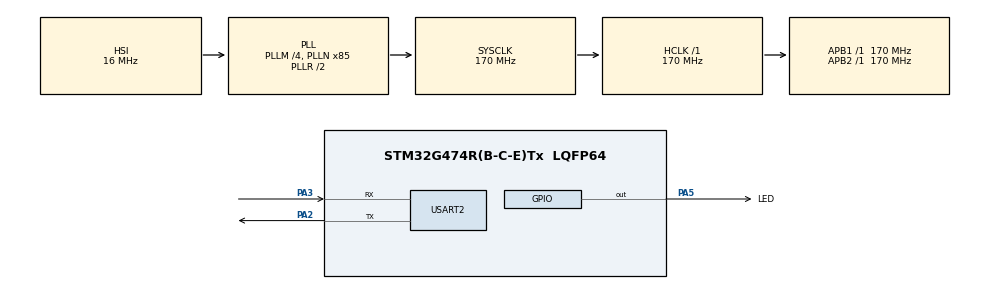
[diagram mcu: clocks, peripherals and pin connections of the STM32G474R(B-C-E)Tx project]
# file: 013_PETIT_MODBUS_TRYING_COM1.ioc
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Mcu.Family=STM32G4
Mcu.Name=STM32G474R(B-C-E)Tx
Mcu.Package=LQFP64
NVIC.PriorityGroup=NVIC_PRIORITYGROUP_4
NVIC.TIM1_UP_TIM16_IRQn=true\:0\:0\:false\:false\:true\:true\:true\:true
NVIC.USART2_IRQn=true\:0\:0\:false\:false\:true\:true\:true\:true
PA13.Mode=Serial_Wire
PA13.Signal=SYS_JTMS-SWDIO
PA14.Mode=Serial_Wire
PA14.Signal=SYS_JTCK-SWCLK
PA2.Mode=Asynchronous
PA2.Signal=USART2_TX
PA2.TagName=VCP_TX
PA3.Mode=Asynchronous
PA3.Signal=USART2_RX
PA3.TagName=VCP_RX
PA5.GPIO_Label=LED
PA5.Signal=GPIO_Output
PA5.TagName=LD2
PC13.TagName=B1
PC14-OSC32_IN.Mode=LSE-External-Oscillator
PC14-OSC32_IN.Signal=RCC_OSC32_IN
PC15-OSC32_OUT.Mode=LSE-External-Oscillator
PC15-OSC32_OUT.Signal=RCC_OSC32_OUT
PF0-OSC_IN.Mode=HSE-External-Oscillator
PF0-OSC_IN.Signal=RCC_OSC_IN
PF1-OSC_OUT.Mode=HSE-External-Oscillator
PF1-OSC_OUT.Signal=RCC_OSC_OUT
ProjectManager.HeapSize=0x200
ProjectManager.StackSize=0x400
ProjectManager.TargetToolchain=STM32CubeIDE
RCC.ADC12Freq_Value=170000000
RCC.ADC345Freq_Value=170000000
RCC.AHBFreq_Value=170000000
RCC.APB1Freq_Value=170000000
RCC.APB1TimFreq_Value=170000000
RCC.APB2Freq_Value=170000000
RCC.APB2TimFreq_Value=170000000
RCC.CortexFreq_Value=170000000
RCC.EXTERNAL_CLOCK_VALUE=12288000
RCC.HCLKFreq_Value=170000000
RCC.HSE_VALUE=24000000
RCC.HSI48_VALUE=48000000
RCC.HSI_VALUE=16000000
RCC.PLLM=RCC_PLLM_DIV4
RCC.PLLN=85
RCC.RTCClockSelection=RCC_RTCCLKSOURCE_LSE
RCC.SYSCLKFreq_VALUE=170000000
RCC.SYSCLKSource=RCC_SYSCLKSOURCE_PLLCLK
RCC.USBFreq_Value=170000000
RCC.VCOOutputFreq_Value=340000000
TIM16.PeriodNoDither=10000
TIM16.Prescaler=17000
USART2.VirtualMode-Asynchronous=VM_ASYNC
VP_SYS_VS_DBSignals.Mode=DisableDeadBatterySignals
VP_TIM16_VS_ClockSourceINT.Mode=Enable_Timer
VP_TIM1_VS_ClockSourceINT.Mode=Internal
board=NUCLEO-G474RE

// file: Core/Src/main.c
/* USER CODE BEGIN Header */
/**
  ******************************************************************************
  * @file           : main.c
  * @brief          : Main program body
  ******************************************************************************
  * @attention
  *
  * Copyright (c) 2024 STMicroelectronics.
  * All rights reserved.
  *
  * This software is licensed under terms that can be found in the LICENSE file
  * in the root directory of this software component.
  * If no LICENSE file comes with this software, it is provided AS-IS.
  *
  ******************************************************************************
  */
/* USER CODE END Header */
#include "main.h"

/* USER CODE BEGIN PD */
#define SLAVEID 1
/* USER CODE END PD */

TIM_HandleTypeDef htim1;
TIM_HandleTypeDef htim16;

UART_HandleTypeDef huart2;

void SystemClock_Config(void);
static void MX_GPIO_Init(void);
static void MX_TIM1_Init(void);
static void MX_TIM16_Init(void);
static void MX_USART2_UART_Init(void);

/* USER CODE BEGIN 0 */
int counter =0;
uint8_t rxbuffer[8];  //GELEN VERIYI TUTACAK BUFFER
uint8_t reg[10] ={0}; //10 ADET HOLDING REGISTER

void CRC16(const unsigned char Data, unsigned int* CRC)
{
    unsigned int i;

    *CRC = *CRC ^(unsigned int) Data;
    for (i = 8; i > 0; i--)
    {
        if (*CRC & 0x0001)
            *CRC = (*CRC >> 1) ^ 0xA001;
        else
            *CRC >>= 1;
    }
}

/* USER CODE END 0 */

int main(void)
{

  /* MCU Configuration--------------------------------------------------------*/

  /* Reset of all peripherals, Initializes the Flash interface and the Systick. */
  HAL_Init();

  /* Configure the system clock */
  SystemClock_Config();

  /* Initialize all configured peripherals */
  MX_GPIO_Init();
  MX_TIM1_Init();
  MX_TIM16_Init();
  MX_USART2_UART_Init();

  /* Infinite loop */
  while (1)
  {

    /* USER CODE BEGIN 3 */

	  HAL_UART_Receive(&huart2, rxbuffer, sizeof(rxbuffer), 100); //MASTERDAN GELEN VERIYI AL

	  if((rxbuffer[0] == SLAVEID) && (rxbuffer[1]= 0x03)){ //EGER GIRILEN SLAVE ADRESI VE FONKSIYON SAGLANIYORSA

		  uint16_t start_Adress = (rxbuffer[2]<<8) | rxbuffer[3] ;
		  uint16_t num_Reg = (rxbuffer[4]<<8) | rxbuffer[5] ;			//TAM ADRESLER OLUSTURULDU

		  uint8_t response[5 + 2*num_Reg+2];
		  response[0] = SLAVEID;
		  response[1] = 0x03;
		  response[2] = 2*num_Reg;
		  for ( int i=0 ; i < num_Reg ; i++){
			  response[3+i*2] = (reg[start_Adress+i] >> 8 ) & 0xFF;
			  response[4+i*2] = reg[start_Adress+i] & 0xFF;
		  }

		  uint8_t crc = CRC16(response,3+2*num_Reg);

		  response[3 + 2 * num_Reg] = crc & 0xFF; // CRC'nin düşük baytı
		  response[4 + 2 * num_Reg] = (crc >> 8) & 0xFF; // CRC'nin yüksek baytı

		  HAL_UART_Transmit(&huart2, response, sizeof(response), 100);
	  }

  }
  /* USER CODE END 3 */
}

void SystemClock_Config(void)
{
  RCC_OscInitTypeDef RCC_OscInitStruct = {0};
  RCC_ClkInitTypeDef RCC_ClkInitStruct = {0};

  /** Configure the main internal regulator output voltage
  */
  HAL_PWREx_ControlVoltageScaling(PWR_REGULATOR_VOLTAGE_SCALE1_BOOST);

  /** Initializes the RCC Oscillators according to the specified parameters
  * in the RCC_OscInitTypeDef structure.
  */
  RCC_OscInitStruct.OscillatorType = RCC_OSCILLATORTYPE_HSI;
  RCC_OscInitStruct.HSIState = RCC_HSI_ON;
  RCC_OscInitStruct.HSICalibrationValue = RCC_HSICALIBRATION_DEFAULT;
  RCC_OscInitStruct.PLL.PLLState = RCC_PLL_ON;
  RCC_OscInitStruct.PLL.PLLSource = RCC_PLLSOURCE_HSI;
  RCC_OscInitStruct.PLL.PLLM = RCC_PLLM_DIV4;
  RCC_OscInitStruct.PLL.PLLN = 85;
  RCC_OscInitStruct.PLL.PLLP = RCC_PLLP_DIV2;
  RCC_OscInitStruct.PLL.PLLQ = RCC_PLLQ_DIV2;
  RCC_OscInitStruct.PLL.PLLR = RCC_PLLR_DIV2;
  if (HAL_RCC_OscConfig(&RCC_OscInitStruct) != HAL_OK)
  {
    Error_Handler();
  }

  /** Initializes the CPU, AHB and APB buses clocks
  */
  RCC_ClkInitStruct.ClockType = RCC_CLOCKTYPE_HCLK|RCC_CLOCKTYPE_SYSCLK
                              |RCC_CLOCKTYPE_PCLK1|RCC_CLOCKTYPE_PCLK2;
  RCC_ClkInitStruct.SYSCLKSource = RCC_SYSCLKSOURCE_PLLCLK;
  RCC_ClkInitStruct.AHBCLKDivider = RCC_SYSCLK_DIV1;
  RCC_ClkInitStruct.APB1CLKDivider = RCC_HCLK_DIV1;
  RCC_ClkInitStruct.APB2CLKDivider = RCC_HCLK_DIV1;

  if (HAL_RCC_ClockConfig(&RCC_ClkInitStruct, FLASH_LATENCY_4) != HAL_OK)
  {
    Error_Handler();
  }
}

static void MX_TIM1_Init(void)
{

  TIM_ClockConfigTypeDef sClockSourceConfig = {0};
  TIM_MasterConfigTypeDef sMasterConfig = {0};

  htim1.Instance = TIM1;
  htim1.Init.Prescaler = 0;
  htim1.Init.CounterMode = TIM_COUNTERMODE_UP;
  htim1.Init.Period = 65535;
  htim1.Init.ClockDivision = TIM_CLOCKDIVISION_DIV1;
  htim1.Init.RepetitionCounter = 0;
  htim1.Init.AutoReloadPreload = TIM_AUTORELOAD_PRELOAD_DISABLE;
  if (HAL_TIM_Base_Init(&htim1) != HAL_OK)
  {
    Error_Handler();
  }
  sClockSourceConfig.ClockSource = TIM_CLOCKSOURCE_INTERNAL;
  if (HAL_TIM_ConfigClockSource(&htim1, &sClockSourceConfig) != HAL_OK)
  {
    Error_Handler();
  }
  sMasterConfig.MasterOutputTrigger = TIM_TRGO_RESET;
  sMasterConfig.MasterOutputTrigger2 = TIM_TRGO2_RESET;
  sMasterConfig.MasterSlaveMode = TIM_MASTERSLAVEMODE_DISABLE;
  if (HAL_TIMEx_MasterConfigSynchronization(&htim1, &sMasterConfig) != HAL_OK)
  {
    Error_Handler();
  }

}

static void MX_TIM16_Init(void)
{

  htim16.Instance = TIM16;
  htim16.Init.Prescaler = 17000;
  htim16.Init.CounterMode = TIM_COUNTERMODE_UP;
  htim16.Init.Period = 10000;
  htim16.Init.ClockDivision = TIM_CLOCKDIVISION_DIV1;
  htim16.Init.RepetitionCounter = 0;
  htim16.Init.AutoReloadPreload = TIM_AUTORELOAD_PRELOAD_DISABLE;
  if (HAL_TIM_Base_Init(&htim16) != HAL_OK)
  {
    Error_Handler();
  }

}

static void MX_USART2_UART_Init(void)
{

  huart2.Instance = USART2;
  huart2.Init.BaudRate = 115200;
  huart2.Init.WordLength = UART_WORDLENGTH_8B;
  huart2.Init.StopBits = UART_STOPBITS_1;
  huart2.Init.Parity = UART_PARITY_NONE;
  huart2.Init.Mode = UART_MODE_TX_RX;
  huart2.Init.HwFlowCtl = UART_HWCONTROL_NONE;
  huart2.Init.OverSampling = UART_OVERSAMPLING_16;
  huart2.Init.OneBitSampling = UART_ONE_BIT_SAMPLE_DISABLE;
  huart2.Init.ClockPrescaler = UART_PRESCALER_DIV1;
  huart2.AdvancedInit.AdvFeatureInit = UART_ADVFEATURE_NO_INIT;
  if (HAL_UART_Init(&huart2) != HAL_OK)
  {
    Error_Handler();
  }
  if (HAL_UARTEx_SetTxFifoThreshold(&huart2, UART_TXFIFO_THRESHOLD_1_8) != HAL_OK)
  {
    Error_Handler();
  }
  if (HAL_UARTEx_SetRxFifoThreshold(&huart2, UART_RXFIFO_THRESHOLD_1_8) != HAL_OK)
  {
    Error_Handler();
  }
  if (HAL_UARTEx_DisableFifoMode(&huart2) != HAL_OK)
  {
    Error_Handler();
  }

}

static void MX_GPIO_Init(void)
{
  GPIO_InitTypeDef GPIO_InitStruct = {0};

  /* GPIO Ports Clock Enable */
  __HAL_RCC_GPIOC_CLK_ENABLE();
  __HAL_RCC_GPIOF_CLK_ENABLE();
  __HAL_RCC_GPIOA_CLK_ENABLE();

  /*Configure GPIO pin Output Level */
  HAL_GPIO_WritePin(LED_GPIO_Port, LED_Pin, GPIO_PIN_RESET);

  /*Configure GPIO pin : LED_Pin */
  GPIO_InitStruct.Pin = LED_Pin;
  GPIO_InitStruct.Mode = GPIO_MODE_OUTPUT_PP;
  GPIO_InitStruct.Pull = GPIO_NOPULL;
  GPIO_InitStruct.Speed = GPIO_SPEED_FREQ_LOW;
  HAL_GPIO_Init(LED_GPIO_Port, &GPIO_InitStruct);

}

void Error_Handler(void)
{
  __disable_irq();
  while (1)
  {
  }
}
